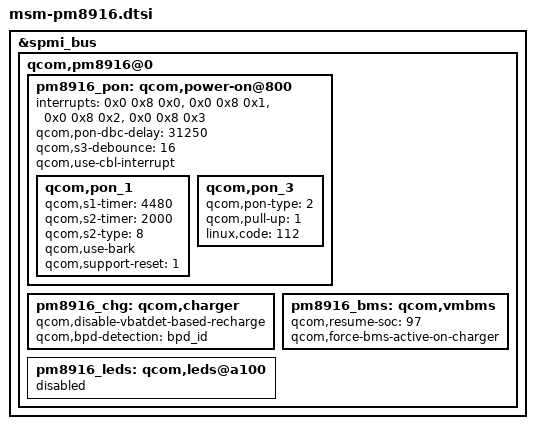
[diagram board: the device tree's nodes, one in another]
/* Copyright (c) 2013-2015, The Linux Foundation. All rights reserved.
 *
 * This program is free software; you can redistribute it and/or modify
 * it under the terms of the GNU General Public License version 2 and
 * only version 2 as published by the Free Software Foundation.
 *
 * This program is distributed in the hope that it will be useful,
 * but WITHOUT ANY WARRANTY; without even the implied warranty of
 * MERCHANTABILITY or FITNESS FOR A PARTICULAR PURPOSE.  See the
 * GNU General Public License for more details.
 */

&spmi_bus {
	qcom,pm8916@0 {
		pm8916_pon: qcom,power-on@800 {
			interrupts = <0x0 0x8 0x0>,
				     <0x0 0x8 0x1>,
				     <0x0 0x8 0x2>,
				     <0x0 0x8 0x3>;
			interrupt-names = "kpdpwr", "resin", "cblpwr", "kpdpwr-bark";
			qcom,pon-dbc-delay = <31250>;
			qcom,s3-debounce = <16>;
			qcom,use-cbl-interrupt;

			qcom,pon_1 {
				qcom,s1-timer = <4480>;
				qcom,s2-timer = <2000>;
				qcom,s2-type = <8>; /* D_VDD hard reset */
				qcom,use-bark;
				qcom,support-reset = <1>;
			};

			qcom,pon_3 {
				qcom,pon-type = <2>;
				qcom,pull-up = <1>;
				linux,code = <112>;
			};
		};

		pm8916_chg: qcom,charger {
			qcom,disable-vbatdet-based-recharge;
			qcom,bpd-detection = "bpd_id";
		};

		pm8916_bms: qcom,vmbms {
			qcom,resume-soc = <97>;
			qcom,force-bms-active-on-charger;
		};

		pm8916_leds: qcom,leds@a100 {
			status = "disabled";
		};
	};
};
